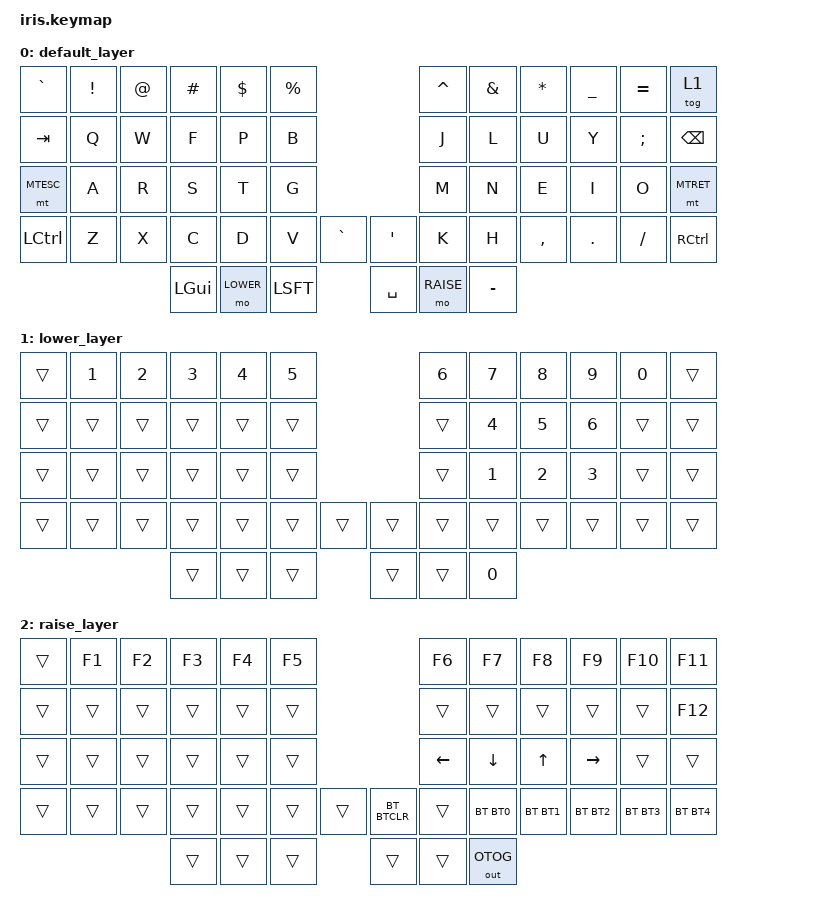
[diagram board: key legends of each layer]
/*
 * Copyright (c) 2020 The ZMK Contributors
 *
 * SPDX-License-Identifier: MIT
 */

#include <behaviors.dtsi>
#include <dt-bindings/zmk/bt.h>
#include <dt-bindings/zmk/keys.h>
#include <dt-bindings/zmk/outputs.h>

#define LOWER 1
#define RAISE 2

#define BTCLR BT_CLR
#define BT0 BT_SEL 0
#define BT1 BT_SEL 1
#define BT2 BT_SEL 2
#define BT3 BT_SEL 3
#define BT4 BT_SEL 4

#define OTOG OUT_TOG

#define MTESC LALT ESC
#define MTRET RALT RET

#define LTSQT RAISE SQT

/ {
  keymap {
    compatible = "zmk,keymap";

    default_layer {
      bindings = <
/*     //┌─────────┬─────────┬─────────┬─────────┬─────────┬─────────┐                          ┌─────────┬─────────┬─────────┬─────────┬─────────┬─────────┐ */
         &kp GRAVE &kp EXCL  &kp AT    &kp HASH  &kp DLLR  &kp PRCNT                            &kp CARET &kp AMPS  &kp STAR  &kp UNDER &kp EQUAL &tog 1  
/*     //├─────────┼─────────┼─────────┼─────────┼─────────┼─────────┤                          ├─────────┼─────────┼─────────┼─────────┼─────────┼─────────┤ */
         &kp TAB   &kp Q     &kp W     &kp F     &kp P     &kp B                                &kp J     &kp L     &kp U     &kp Y     &kp SEMI  &kp BSPC
/*     //├─────────┼─────────┼─────────┼─────────┼─────────┼─────────┤                          ├─────────┼─────────┼─────────┼─────────┼─────────┼─────────┤ */
         &mt MTESC &kp A     &kp R     &kp S     &kp T     &kp G                                &kp M     &kp N     &kp E     &kp I     &kp O     &mt MTRET
/*     //├─────────┼─────────┼─────────┼─────────┼─────────┼─────────┼─────────┐      ┌─────────┼─────────┼─────────┼─────────┼─────────┼─────────┼─────────┤ */
         &kp LCTL  &kp Z     &kp X     &kp C     &kp D     &kp V     &kp GRAVE        &kp SQT   &kp K     &kp H     &kp COMMA &kp DOT   &kp FSLH  &kp RCTL
/*     //└─────────┴─────────┴─────────┴────┬────┴────┬────┴────┬────┴────┬────┘      └────┬────┴────┬────┴────┬────┴────┬────┴─────────┴─────────┴─────────┘ */
                                            &kp LGUI  &mo LOWER &kp LSFT                   &kp SPACE &mo RAISE &kp MINUS
/*                                       // └─────────┴─────────┴─────────┘                └─────────┴─────────┴─────────┘ */
      >;
    };

    lower_layer {
      bindings = <
/*     //┌─────────┬─────────┬─────────┬─────────┬─────────┬─────────┐                          ┌─────────┬─────────┬─────────┬─────────┬─────────┬─────────┐ */
         &trans    &kp N1    &kp N2    &kp N3    &kp N4    &kp N5                               &kp N6    &kp N7    &kp N8    &kp N9    &kp N0    &trans   
/*     //├─────────┼─────────┼─────────┼─────────┼─────────┼─────────┤                          ├─────────┼─────────┼─────────┼─────────┼─────────┼─────────┤ */
         &trans    &trans    &trans    &trans    &trans    &trans                               &trans    &kp N4    &kp N5    &kp N6    &trans    &trans    
/*     //├─────────┼─────────┼─────────┼─────────┼─────────┼─────────┤                          ├─────────┼─────────┼─────────┼─────────┼─────────┼─────────┤ */
         &trans    &trans    &trans    &trans    &trans    &trans                               &trans    &kp N1    &kp N2    &kp N3    &trans    &trans   
/*     //├─────────┼─────────┼─────────┼─────────┼─────────┼─────────┼─────────┐      ┌─────────┼─────────┼─────────┼─────────┼─────────┼─────────┼─────────┤ */
         &trans    &trans    &trans    &trans    &trans    &trans    &trans           &trans    &trans    &trans    &trans    &trans    &trans    &trans    
/*     //└─────────┴─────────┴─────────┴────┬────┴────┬────┴────┬────┴────┬────┘      └────┬────┴────┬────┴────┬────┴────┬────┴─────────┴─────────┴─────────┘ */
                                            &trans    &trans    &trans                     &trans    &trans    &kp N0
/*                                       // └─────────┴─────────┴─────────┘                └─────────┴─────────┴─────────┘ */
      >;
    };

    raise_layer {
      bindings = <
/*     //┌─────────┬─────────┬─────────┬─────────┬─────────┬─────────┐                          ┌─────────┬─────────┬─────────┬─────────┬─────────┬─────────┐ */
         &trans    &kp F1    &kp F2    &kp F3    &kp F4    &kp F5                               &kp F6    &kp F7    &kp F8    &kp F9    &kp F10   &kp F11   
/*     //├─────────┼─────────┼─────────┼─────────┼─────────┼─────────┤                          ├─────────┼─────────┼─────────┼─────────┼─────────┼─────────┤ */
         &trans    &trans    &trans    &trans    &trans    &trans                               &trans    &trans    &trans    &trans    &trans    &kp F12   
/*     //├─────────┼─────────┼─────────┼─────────┼─────────┼─────────┤                          ├─────────┼─────────┼─────────┼─────────┼─────────┼─────────┤ */
         &trans    &trans    &trans    &trans    &trans    &trans                               &kp LEFT  &kp DOWN  &kp UP    &kp RIGHT &trans    &trans    
/*     //├─────────┼─────────┼─────────┼─────────┼─────────┼─────────┼─────────┐      ┌─────────┼─────────┼─────────┼─────────┼─────────┼─────────┼─────────┤ */
         &trans    &trans    &trans    &trans    &trans    &trans    &trans           &bt BTCLR &trans    &bt BT0   &bt BT1   &bt BT2   &bt BT3   &bt BT4   
/*     //└─────────┴─────────┴─────────┴────┬────┴────┬────┴────┬────┴────┬────┘      └────┬────┴────┬────┴────┬────┴────┬────┴─────────┴─────────┴─────────┘ */
                                            &trans    &trans    &trans                     &trans    &trans    &out OTOG
/*                                       // └─────────┴─────────┴─────────┘                └─────────┴─────────┴─────────┘ */
      >;
    };
  };
};

/ {
  combos {
    compatible = "zmk,combos";

    combo_lsft {
      timeout-ms = <50>;
      key-positions = <52 42>;
      bindings = <&kp LSFT>;
    };

    combo_rsft {
      timeout-ms = <50>;
      key-positions = <53 43>;
      bindings = <&kp RSFT>;
    };
  };
};
